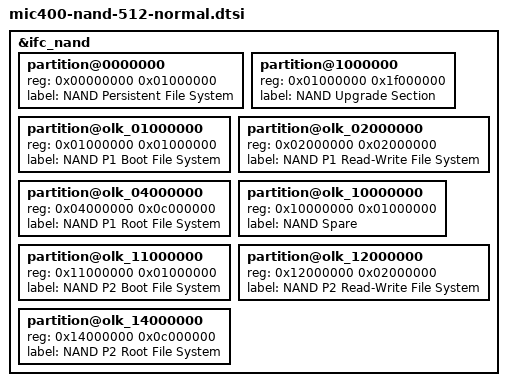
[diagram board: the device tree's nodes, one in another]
/*
 * MIC400 Device Tree Source
 *
 * Copyright 2013 OMICRON electronics GmbH.
 *
 * This program is free software; you can redistribute	it and/or modify it
 * under  the terms of	the GNU General	 Public License as published by the
 * Free Software Foundation;  either version 2 of the  License, or (at your
 * option) any later version.
 */

&ifc_nand {
	partition@0000000      { reg = <0x00000000 0x01000000>; label = "NAND Persistent File System"; };
	partition@1000000      { reg = <0x01000000 0x1f000000>; label = "NAND Upgrade Section"; };

	partition@olk_01000000 { reg = <0x01000000 0x01000000>; label = "NAND P1 Boot File System"; };
	partition@olk_02000000 { reg = <0x02000000 0x02000000>; label = "NAND P1 Read-Write File System"; };
	partition@olk_04000000 { reg = <0x04000000 0x0c000000>; label = "NAND P1 Root File System"; };
	partition@olk_10000000 { reg = <0x10000000 0x01000000>; label = "NAND Spare"; };
	partition@olk_11000000 { reg = <0x11000000 0x01000000>; label = "NAND P2 Boot File System"; };
	partition@olk_12000000 { reg = <0x12000000 0x02000000>; label = "NAND P2 Read-Write File System"; };
	partition@olk_14000000 { reg = <0x14000000 0x0c000000>; label = "NAND P2 Root File System"; };
};
